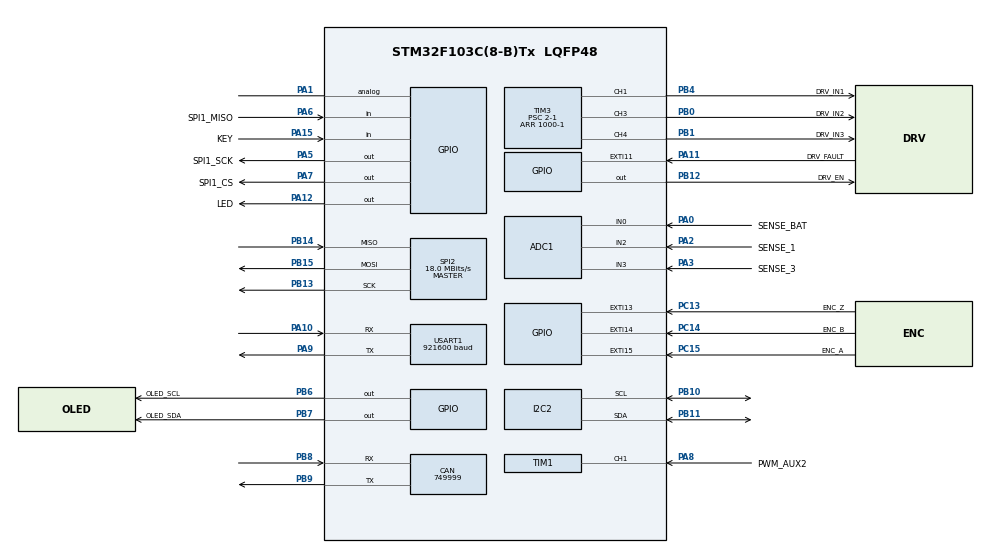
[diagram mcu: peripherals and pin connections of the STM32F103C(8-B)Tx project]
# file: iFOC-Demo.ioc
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ADC1.Channel-0\#ChannelRegularConversion=ADC_CHANNEL_0
ADC1.Channel-1\#ChannelRegularConversion=ADC_CHANNEL_2
ADC1.Channel-2\#ChannelRegularConversion=ADC_CHANNEL_3
ADC1.Channel-3\#ChannelRegularConversion=ADC_CHANNEL_VREFINT
ADC1.Channel-4\#ChannelRegularConversion=ADC_CHANNEL_TEMPSENSOR
ADC1.ContinuousConvMode=ENABLE
ADC1.NbrOfConversion=5
ADC1.NbrOfConversionFlag=1
ADC1.Rank-0\#ChannelRegularConversion=1
ADC1.Rank-1\#ChannelRegularConversion=2
ADC1.Rank-2\#ChannelRegularConversion=3
ADC1.Rank-3\#ChannelRegularConversion=4
ADC1.Rank-4\#ChannelRegularConversion=5
ADC1.SamplingTime-0\#ChannelRegularConversion=ADC_SAMPLETIME_239CYCLES_5
ADC1.SamplingTime-1\#ChannelRegularConversion=ADC_SAMPLETIME_239CYCLES_5
ADC1.SamplingTime-2\#ChannelRegularConversion=ADC_SAMPLETIME_239CYCLES_5
ADC1.SamplingTime-3\#ChannelRegularConversion=ADC_SAMPLETIME_239CYCLES_5
ADC1.SamplingTime-4\#ChannelRegularConversion=ADC_SAMPLETIME_239CYCLES_5
ADC1.master=1
CAN.CalculateBaudRate=749999
CAN.CalculateTimeBit=1333
CAN.CalculateTimeQuantum=444.44444444444446
Dma.ADC1.2.Direction=DMA_PERIPH_TO_MEMORY
Dma.ADC1.2.Instance=DMA1_Channel1
Dma.ADC1.2.MemDataAlignment=DMA_MDATAALIGN_HALFWORD
Dma.ADC1.2.MemInc=DMA_MINC_ENABLE
Dma.ADC1.2.Mode=DMA_CIRCULAR
Dma.ADC1.2.PeriphDataAlignment=DMA_PDATAALIGN_HALFWORD
Dma.ADC1.2.PeriphInc=DMA_PINC_DISABLE
Dma.ADC1.2.Priority=DMA_PRIORITY_LOW
Dma.Request0=USART1_RX
Dma.Request1=USART1_TX
Dma.Request2=ADC1
Dma.USART1_RX.0.Direction=DMA_PERIPH_TO_MEMORY
Dma.USART1_RX.0.Instance=DMA1_Channel5
Dma.USART1_RX.0.MemDataAlignment=DMA_MDATAALIGN_BYTE
Dma.USART1_RX.0.MemInc=DMA_MINC_ENABLE
Dma.USART1_RX.0.Mode=DMA_CIRCULAR
Dma.USART1_RX.0.PeriphDataAlignment=DMA_PDATAALIGN_BYTE
Dma.USART1_RX.0.PeriphInc=DMA_PINC_DISABLE
Dma.USART1_RX.0.Priority=DMA_PRIORITY_LOW
Dma.USART1_TX.1.Direction=DMA_MEMORY_TO_PERIPH
Dma.USART1_TX.1.Instance=DMA1_Channel4
Dma.USART1_TX.1.MemDataAlignment=DMA_MDATAALIGN_BYTE
Dma.USART1_TX.1.MemInc=DMA_MINC_ENABLE
Dma.USART1_TX.1.Mode=DMA_NORMAL
Dma.USART1_TX.1.PeriphDataAlignment=DMA_PDATAALIGN_BYTE
Dma.USART1_TX.1.PeriphInc=DMA_PINC_DISABLE
Dma.USART1_TX.1.Priority=DMA_PRIORITY_LOW
FREERTOS.Tasks01=defaultTask,0,128,StartDefaultTask,Default,NULL,Dynamic,NULL,NULL
FREERTOS.configLIBRARY_MAX_SYSCALL_INTERRUPT_PRIORITY=5
FREERTOS.configMAX_PRIORITIES=32
FREERTOS.configTOTAL_HEAP_SIZE=12288
Mcu.Family=STM32F1
Mcu.Name=STM32F103C(8-B)Tx
Mcu.Package=LQFP48
NVIC.DMA1_Channel5_IRQn=true\:5\:0\:false\:false\:true\:true\:false\:true\:true
NVIC.EXTI15_10_IRQn=true\:5\:0\:false\:false\:true\:true\:true\:true\:true
NVIC.PriorityGroup=NVIC_PRIORITYGROUP_4
NVIC.TIM2_IRQn=true\:6\:0\:true\:false\:true\:false\:true\:true\:true
NVIC.TIM4_IRQn=true\:15\:0\:false\:false\:true\:false\:false\:true\:true
NVIC.TimeBase=TIM4_IRQn
NVIC.TimeBaseIP=TIM4
NVIC.USART1_IRQn=true\:5\:0\:true\:false\:true\:true\:true\:true\:true
PA0-WKUP.GPIO_Label=SENSE_BAT
PA0-WKUP.Signal=ADCx_IN0
PA1.Signal=GPIO_Analog
PA10.Mode=Asynchronous
PA10.Signal=USART1_RX
PA11.GPIO_Label=DRV_FAULT
PA11.GPIO_ModeDefaultEXTI=GPIO_MODE_IT_RISING_FALLING
PA11.GPIO_PuPd=GPIO_PULLUP
PA11.Signal=GPXTI11
PA12.GPIO_Label=LED
PA12.GPIO_Speed=GPIO_SPEED_FREQ_HIGH
PA12.Signal=GPIO_Output
PA13.Mode=Serial_Wire
PA13.Signal=SYS_JTMS-SWDIO
PA14.Mode=Serial_Wire
PA14.Signal=SYS_JTCK-SWCLK
PA15.GPIO_Label=KEY
PA15.GPIO_PuPd=GPIO_PULLUP
PA15.Signal=GPIO_Input
PA2.GPIO_Label=SENSE_1
PA2.Signal=ADCx_IN2
PA3.GPIO_Label=SENSE_3
PA3.Signal=ADCx_IN3
PA5.GPIO_Label=SPI1_SCK
PA5.GPIO_PuPd=GPIO_PULLDOWN
PA5.GPIO_Speed=GPIO_SPEED_FREQ_HIGH
PA5.Signal=GPIO_Output
PA6.GPIO_Label=SPI1_MISO
PA6.GPIO_PuPd=GPIO_PULLUP
PA6.Signal=GPIO_Input
PA7.GPIO_Label=SPI1_CS
PA7.GPIO_PuPd=GPIO_PULLUP
PA7.GPIO_Speed=GPIO_SPEED_FREQ_HIGH
PA7.PinState=GPIO_PIN_SET
PA7.Signal=GPIO_Output
PA8.GPIO_Label=PWM_AUX2
PA8.GPIO_PuPd=GPIO_PULLDOWN
PA8.GPIO_Speed=GPIO_SPEED_FREQ_HIGH
PA8.Signal=S_TIM1_CH1
PA9.Mode=Asynchronous
PA9.Signal=USART1_TX
PB0.GPIO_Label=DRV_IN2
PB0.GPIO_Speed=GPIO_SPEED_FREQ_HIGH
PB0.Signal=S_TIM3_CH3
PB1.GPIO_Label=DRV_IN3
PB1.GPIO_Speed=GPIO_SPEED_FREQ_HIGH
PB1.Signal=S_TIM3_CH4
PB10.Mode=I2C
PB10.Signal=I2C2_SCL
PB11.Mode=I2C
PB11.Signal=I2C2_SDA
PB12.GPIO_Label=DRV_EN
PB12.GPIO_Speed=GPIO_SPEED_FREQ_HIGH
PB12.Signal=GPIO_Output
PB13.Mode=Full_Duplex_Master
PB13.Signal=SPI2_SCK
PB14.Mode=Full_Duplex_Master
PB14.Signal=SPI2_MISO
PB15.Mode=Full_Duplex_Master
PB15.Signal=SPI2_MOSI
PB4.GPIO_Label=DRV_IN1
PB4.GPIO_Speed=GPIO_SPEED_FREQ_HIGH
PB4.Signal=S_TIM3_CH1
PB6.GPIO_Label=OLED_SCL
PB6.GPIO_PuPd=GPIO_PULLUP
PB6.GPIO_Speed=GPIO_SPEED_FREQ_HIGH
PB6.Signal=GPIO_Output
PB7.GPIO_Label=OLED_SDA
PB7.GPIO_PuPd=GPIO_PULLUP
PB7.GPIO_Speed=GPIO_SPEED_FREQ_HIGH
PB7.PinState=GPIO_PIN_SET
PB7.Signal=GPIO_Output
PB8.Mode=CAN_Activate
PB8.Signal=CAN_RX
PB9.Mode=CAN_Activate
PB9.Signal=CAN_TX
PC13-TAMPER-RTC.GPIO_Label=ENC_Z
PC13-TAMPER-RTC.Signal=GPXTI13
PC14-OSC32_IN.GPIO_Label=ENC_B
PC14-OSC32_IN.Signal=GPXTI14
PC15-OSC32_OUT.GPIO_Label=ENC_A
PC15-OSC32_OUT.Signal=GPXTI15
PD0-OSC_IN.Mode=HSE-External-Oscillator
PD0-OSC_IN.Signal=RCC_OSC_IN
PD1-OSC_OUT.Mode=HSE-External-Oscillator
PD1-OSC_OUT.Signal=RCC_OSC_OUT
ProjectManager.HeapSize=0x200
ProjectManager.StackSize=0x400
ProjectManager.TargetToolchain=Makefile
RCC.ADCPresc=RCC_ADCPCLK2_DIV6
RCC.AHBFreq_Value=72000000
RCC.APB1CLKDivider=RCC_HCLK_DIV2
RCC.APB1Freq_Value=36000000
RCC.APB1TimFreq_Value=72000000
RCC.APB2Freq_Value=72000000
RCC.APB2TimFreq_Value=72000000
RCC.EnbaleCSS=true
RCC.HCLKFreq_Value=72000000
RCC.PLLMUL=RCC_PLL_MUL9
RCC.PLLSourceVirtual=RCC_PLLSOURCE_HSE
RCC.SYSCLKFreq_VALUE=72000000
RCC.SYSCLKSource=RCC_SYSCLKSOURCE_PLLCLK
RCC.USBFreq_Value=72000000
SH.ADCx_IN0.0=ADC1_IN0,IN0
SH.ADCx_IN2.0=ADC1_IN2,IN2
SH.ADCx_IN3.0=ADC1_IN3,IN3
SH.S_TIM1_CH1.0=TIM1_CH1,PWM_Input_1
SH.S_TIM3_CH1.0=TIM3_CH1,PWM Generation1 CH1
SH.S_TIM3_CH3.0=TIM3_CH3,PWM Generation3 CH3
SH.S_TIM3_CH4.0=TIM3_CH4,PWM Generation4 CH4
SPI2.CalculateBaudRate=18.0 MBits/s
SPI2.Direction=SPI_DIRECTION_2LINES
SPI2.Mode=SPI_MODE_MASTER
SPI2.VirtualType=VM_MASTER
TIM1.AutoReloadPreload=TIM_AUTORELOAD_PRELOAD_ENABLE
TIM1.ICFilter_1=0
TIM1.ICFilter_2=0
TIM1.Period=65535
TIM1.Prescaler=72-1
TIM2.AutoReloadPreload=TIM_AUTORELOAD_PRELOAD_ENABLE
TIM2.Period=400-1
TIM2.Prescaler=72-1
TIM3.AutoReloadPreload=TIM_AUTORELOAD_PRELOAD_ENABLE
TIM3.Channel-PWM\ Generation1\ CH1=TIM_CHANNEL_1
TIM3.Channel-PWM\ Generation3\ CH3=TIM_CHANNEL_3
TIM3.Channel-PWM\ Generation4\ CH4=TIM_CHANNEL_4
TIM3.Period=1000-1
TIM3.Prescaler=2-1
USART1.BaudRate=921600
USART1.VirtualMode=VM_ASYNC
VP_ADC1_TempSens_Input.Mode=IN-TempSens
VP_ADC1_Vref_Input.Mode=IN-Vrefint
VP_FREERTOS_VS_CMSIS_V1.Mode=CMSIS_V1
VP_SYS_VS_tim4.Mode=TIM4
VP_TIM2_VS_ClockSourceINT.Mode=Internal
board=custom

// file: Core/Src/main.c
/* USER CODE BEGIN Header */
/**
  ******************************************************************************
  * @file           : main.c
  * @brief          : Main program body
  ******************************************************************************
  * @attention
  *
  * Copyright (c) 2023 STMicroelectronics.
  * All rights reserved.
  *
  * This software is licensed under terms that can be found in the LICENSE file
  * in the root directory of this software component.
  * If no LICENSE file comes with this software, it is provided AS-IS.
  *
  ******************************************************************************
  */
/* USER CODE END Header */
#include "main.h"
#include "cmsis_os.h"
#include "adc.h"
#include "can.h"
#include "dma.h"
#include "i2c.h"
#include "spi.h"
#include "tim.h"
#include "usart.h"
#include "gpio.h"

/* USER CODE BEGIN Includes */
#include "foc.h"
/* USER CODE END Includes */

/* USER CODE BEGIN PTD */
FOC_TypeDef foc_driver;
/* USER CODE END PTD */

void SystemClock_Config(void);
void MX_FREERTOS_Init(void);

int main(void)
{

  /* MCU Configuration--------------------------------------------------------*/

  /* Reset of all peripherals, Initializes the Flash interface and the Systick. */
  HAL_Init();

  /* Configure the system clock */
  SystemClock_Config();

  /* Initialize all configured peripherals */
  MX_GPIO_Init();
  MX_DMA_Init();
  MX_CAN_Init();
  MX_SPI2_Init();
  MX_USART1_UART_Init();
  MX_ADC1_Init();
  MX_I2C2_Init();
  MX_TIM3_Init();
  MX_TIM1_Init();
  MX_TIM2_Init();
  /* USER CODE BEGIN 2 */
  DWT_Delay_Init();
  // PWM_Encoder_HardwareInit_LL(TIM1);
  SPI_Encoder_Init();
  ADC_HandlerInit(&hadc1);
  foc_driver = FOC_Driver_Init(12.0f);
  UART_HandlerInit(&huart1);
  // OLED_Init();
  // OLED_printf(0, 0, 12, "iFOC: Hello World!");
  // OLED_RefreshGram();
  /* USER CODE END 2 */

  /* Call init function for freertos objects (in freertos.c) */
  MX_FREERTOS_Init();

  /* Start scheduler */
  osKernelStart();

  /* We should never get here as control is now taken by the scheduler */
  /* Infinite loop */
  while (1)
  {

  }
}

void SystemClock_Config(void)
{
  LL_FLASH_SetLatency(LL_FLASH_LATENCY_2);
  while(LL_FLASH_GetLatency()!= LL_FLASH_LATENCY_2)
  {
  }
  LL_RCC_HSE_Enable();

   /* Wait till HSE is ready */
  while(LL_RCC_HSE_IsReady() != 1)
  {

  }
  LL_RCC_HSE_EnableCSS();
  LL_RCC_PLL_ConfigDomain_SYS(LL_RCC_PLLSOURCE_HSE_DIV_1, LL_RCC_PLL_MUL_9);
  LL_RCC_PLL_Enable();

   /* Wait till PLL is ready */
  while(LL_RCC_PLL_IsReady() != 1)
  {

  }
  LL_RCC_SetAHBPrescaler(LL_RCC_SYSCLK_DIV_1);
  LL_RCC_SetAPB1Prescaler(LL_RCC_APB1_DIV_2);
  LL_RCC_SetAPB2Prescaler(LL_RCC_APB2_DIV_1);
  LL_RCC_SetSysClkSource(LL_RCC_SYS_CLKSOURCE_PLL);

   /* Wait till System clock is ready */
  while(LL_RCC_GetSysClkSource() != LL_RCC_SYS_CLKSOURCE_STATUS_PLL)
  {

  }
  LL_SetSystemCoreClock(72000000);

   /* Update the time base */
  if (HAL_InitTick (TICK_INT_PRIORITY) != HAL_OK)
  {
    Error_Handler();
  }
  LL_RCC_SetADCClockSource(LL_RCC_ADC_CLKSRC_PCLK2_DIV_6);
}

void HAL_TIM_PeriodElapsedCallback(TIM_HandleTypeDef *htim)
{
  if (htim->Instance == TIM4) {
    HAL_IncTick();
  }
}

void Error_Handler(void)
{
  __disable_irq();
  while (1)
  {
  }
}

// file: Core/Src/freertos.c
/* USER CODE BEGIN Header */
/**
  ******************************************************************************
  * File Name          : freertos.c
  * Description        : Code for freertos applications
  ******************************************************************************
  * @attention
  *
  * Copyright (c) 2023 STMicroelectronics.
  * All rights reserved.
  *
  * This software is licensed under terms that can be found in the LICENSE file
  * in the root directory of this software component.
  * If no LICENSE file comes with this software, it is provided AS-IS.
  *
  ******************************************************************************
  */
/* USER CODE END Header */

#include "FreeRTOS.h"
#include "task.h"
#include "main.h"
#include "cmsis_os.h"

/* USER CODE BEGIN Includes */
#include "user_task.h"
/* USER CODE END Includes */

osThreadId defaultTaskHandle;

void StartDefaultTask(void const * argument);

void MX_FREERTOS_Init(void); /* (MISRA C 2004 rule 8.1) */

/* GetIdleTaskMemory prototype (linked to static allocation support) */
void vApplicationGetIdleTaskMemory( StaticTask_t **ppxIdleTaskTCBBuffer, StackType_t **ppxIdleTaskStackBuffer, uint32_t *pulIdleTaskStackSize );

/* USER CODE BEGIN GET_IDLE_TASK_MEMORY */
static StaticTask_t xIdleTaskTCBBuffer;
static StackType_t xIdleStack[configMINIMAL_STACK_SIZE];

void vApplicationGetIdleTaskMemory( StaticTask_t **ppxIdleTaskTCBBuffer, StackType_t **ppxIdleTaskStackBuffer, uint32_t *pulIdleTaskStackSize )
{
  *ppxIdleTaskTCBBuffer = &xIdleTaskTCBBuffer;
  *ppxIdleTaskStackBuffer = &xIdleStack[0];
  *pulIdleTaskStackSize = configMINIMAL_STACK_SIZE;
  /* place for user code */
}
/* USER CODE END GET_IDLE_TASK_MEMORY */

void MX_FREERTOS_Init(void) {

  /* Create the thread(s) */
  /* definition and creation of defaultTask */
  osThreadDef(defaultTask, StartDefaultTask, osPriorityNormal, 0, 128);
  defaultTaskHandle = osThreadCreate(osThread(defaultTask), NULL);

}

void StartDefaultTask(void const * argument)
{
  /* USER CODE BEGIN StartDefaultTask */
  /* Infinite loop */
  StartUserTask();
  /* USER CODE END StartDefaultTask */
}
